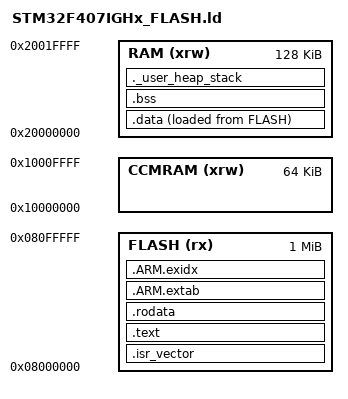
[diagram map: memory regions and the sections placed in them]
/* RoboMaster Development Board Type C: STM32F407IGHx, 1 MiB Flash. */
ENTRY(Reset_Handler)

_estack = ORIGIN(RAM) + LENGTH(RAM);
_Min_Heap_Size = 0x200;
_Min_Stack_Size = 0x400;

MEMORY
{
  FLASH (rx)  : ORIGIN = 0x08000000, LENGTH = 1M
  RAM (xrw)   : ORIGIN = 0x20000000, LENGTH = 128K
  CCMRAM (xrw): ORIGIN = 0x10000000, LENGTH = 64K
}

SECTIONS
{
  .isr_vector :
  {
    . = ALIGN(4);
    KEEP(*(.isr_vector))
    . = ALIGN(4);
  } >FLASH

  .text :
  {
    . = ALIGN(4);
    *(.text)
    *(.text*)
    *(.glue_7)
    *(.glue_7t)
    *(.eh_frame)
    KEEP(*(.init))
    KEEP(*(.fini))
    . = ALIGN(4);
    _etext = .;
  } >FLASH

  .rodata :
  {
    . = ALIGN(4);
    *(.rodata)
    *(.rodata*)
    . = ALIGN(4);
  } >FLASH

  .ARM.extab :
  {
    *(.ARM.extab* .gnu.linkonce.armextab.*)
  } >FLASH

  .ARM.exidx :
  {
    __exidx_start = .;
    *(.ARM.exidx* .gnu.linkonce.armexidx.*)
    __exidx_end = .;
  } >FLASH

  _sidata = LOADADDR(.data);
  .data :
  {
    . = ALIGN(4);
    _sdata = .;
    *(.data)
    *(.data*)
    . = ALIGN(4);
    _edata = .;
  } >RAM AT> FLASH

  .bss :
  {
    . = ALIGN(4);
    _sbss = .;
    *(.bss)
    *(.bss*)
    *(COMMON)
    . = ALIGN(4);
    _ebss = .;
  } >RAM

  ._user_heap_stack :
  {
    . = ALIGN(8);
    PROVIDE(end = .);
    PROVIDE(_end = .);
    . = . + _Min_Heap_Size;
    . = . + _Min_Stack_Size;
    . = ALIGN(8);
  } >RAM

  /DISCARD/ :
  {
    libm.a ( * )
    libc.a ( * )
    libgcc.a ( * )
  }

  .ARM.attributes 0 : { *(.ARM.attributes) }
}
